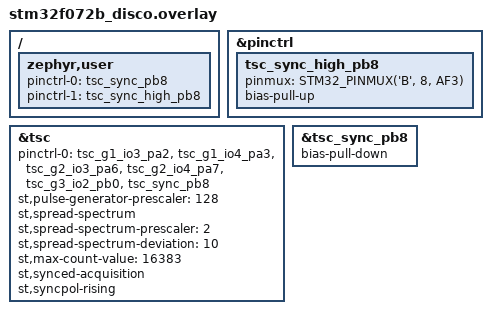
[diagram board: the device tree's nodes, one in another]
/*
 * Copyright (c) 2024 Arif Balik <arifbalik@outlook.com>
 * SPDX-License-Identifier: Apache-2.0
 */

/ {
	zephyr,user {
		/* The test switches the SYNC pin between these two states: pulled low
		 * keeps the synchronized acquisition waiting, pulled high lets it run.
		 */
		pinctrl-0 = <&tsc_sync_pb8>;
		pinctrl-1 = <&tsc_sync_high_pb8>;
		pinctrl-names = "default", "sync_high";
	};
};

&pinctrl {
	tsc_sync_high_pb8: tsc_sync_high_pb8 {
		pinmux = <STM32_PINMUX('B', 8, AF3)>;
		bias-pull-up;
	};
};

&tsc {

	pinctrl-0 = <&tsc_g1_io3_pa2 &tsc_g1_io4_pa3 &tsc_g2_io3_pa6 &tsc_g2_io4_pa7 &tsc_g3_io2_pb0
		     &tsc_sync_pb8>;
	pinctrl-names = "default";

	st,pulse-generator-prescaler = <128>;

	st,spread-spectrum;
	st,spread-spectrum-prescaler = <2>;
	st,spread-spectrum-deviation = <10>;

	st,max-count-value = <16383>;

	st,synced-acquisition;
	st,syncpol-rising;
	status = "okay";
};

/* A floating SYNC pin starts acquisitions on its own, keep it low by default. */
&tsc_sync_pb8 {
	bias-pull-down;
};
